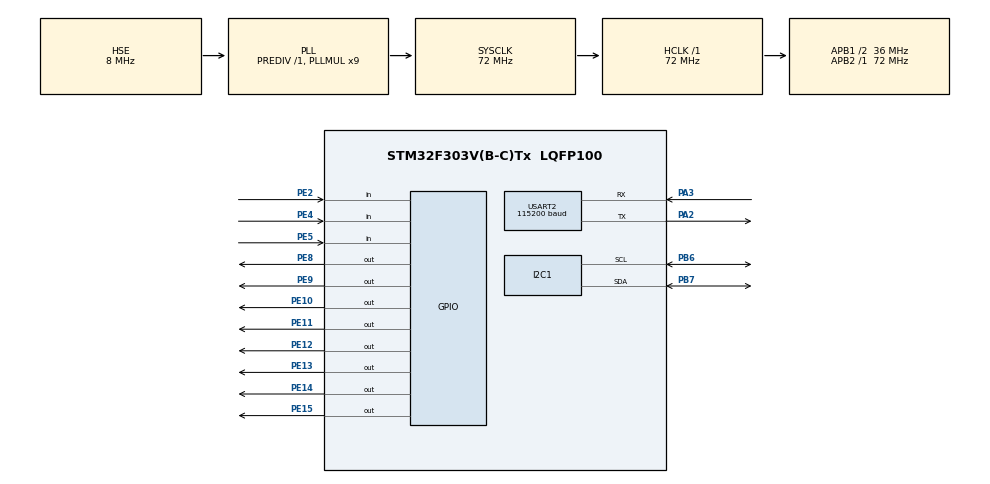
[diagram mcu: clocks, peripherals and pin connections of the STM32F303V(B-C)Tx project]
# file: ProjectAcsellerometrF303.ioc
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I2C1.Timing=0x2000090E
Mcu.Family=STM32F3
Mcu.Name=STM32F303V(B-C)Tx
Mcu.Package=LQFP100
NVIC.PriorityGroup=NVIC_PRIORITYGROUP_4
PA2.Mode=Asynchronous
PA2.Signal=USART2_TX
PA3.Mode=Asynchronous
PA3.Signal=USART2_RX
PB6.Mode=I2C
PB6.Signal=I2C1_SCL
PB7.Mode=I2C
PB7.Signal=I2C1_SDA
PE10.Signal=GPIO_Output
PE11.Signal=GPIO_Output
PE12.Signal=GPIO_Output
PE13.Signal=GPIO_Output
PE14.Signal=GPIO_Output
PE15.Signal=GPIO_Output
PE2.Signal=GPIO_Input
PE4.Signal=GPIO_Input
PE5.Signal=GPIO_Input
PE8.Signal=GPIO_Output
PE9.Signal=GPIO_Output
PF0-OSC_IN.Mode=HSE-External-Oscillator
PF0-OSC_IN.Signal=RCC_OSC_IN
PF1-OSC_OUT.Mode=HSE-External-Oscillator
PF1-OSC_OUT.Signal=RCC_OSC_OUT
ProjectManager.HeapSize=0x200
ProjectManager.StackSize=0x400
ProjectManager.TargetToolchain=MDK-ARM V5
RCC.AHBFreq_Value=72000000
RCC.APB1CLKDivider=RCC_HCLK_DIV2
RCC.APB1Freq_Value=36000000
RCC.APB1TimFreq_Value=72000000
RCC.APB2Freq_Value=72000000
RCC.APB2TimFreq_Value=72000000
RCC.CortexFreq_Value=72000000
RCC.HCLKFreq_Value=72000000
RCC.HSE_VALUE=8000000
RCC.HSI_VALUE=8000000
RCC.LSE_VALUE=32768
RCC.PLLMUL=RCC_PLL_MUL9
RCC.PLLSourceVirtual=RCC_PLLSOURCE_HSE
RCC.SYSCLKFreq_VALUE=72000000
RCC.SYSCLKSourceVirtual=RCC_SYSCLKSOURCE_PLLCLK
RCC.USBFreq_Value=72000000
USART2.BaudRate=115200
USART2.VirtualMode-Asynchronous=VM_ASYNC
board=ProjectAcsellerometrF303

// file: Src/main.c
/**
  ******************************************************************************
  * File Name          : main.c
  * Description        : Main program body
  ******************************************************************************
  ** This notice applies to any and all portions of this file
  * that are not between comment pairs USER CODE BEGIN and
  * USER CODE END. Other portions of this file, whether
  * inserted by the user or by software development tools
  * are owned by their respective copyright owners.
  *
  * COPYRIGHT(c) 2017 STMicroelectronics
  *
  * Redistribution and use in source and binary forms, with or without modification,
  * are permitted provided that the following conditions are met:
  *   1. Redistributions of source code must retain the above copyright notice,
  *      this list of conditions and the following disclaimer.
  *   2. Redistributions in binary form must reproduce the above copyright notice,
  *      this list of conditions and the following disclaimer in the documentation
  *      and/or other materials provided with the distribution.
  *   3. Neither the name of STMicroelectronics nor the names of its contributors
  *      may be used to endorse or promote products derived from this software
  *      without specific prior written permission.
  *
  * THIS SOFTWARE IS PROVIDED BY THE COPYRIGHT HOLDERS AND CONTRIBUTORS "AS IS"
  * AND ANY EXPRESS OR IMPLIED WARRANTIES, INCLUDING, BUT NOT LIMITED TO, THE
  * IMPLIED WARRANTIES OF MERCHANTABILITY AND FITNESS FOR A PARTICULAR PURPOSE ARE
  * DISCLAIMED. IN NO EVENT SHALL THE COPYRIGHT HOLDER OR CONTRIBUTORS BE LIABLE
  * FOR ANY DIRECT, INDIRECT, INCIDENTAL, SPECIAL, EXEMPLARY, OR CONSEQUENTIAL
  * DAMAGES (INCLUDING, BUT NOT LIMITED TO, PROCUREMENT OF SUBSTITUTE GOODS OR
  * SERVICES; LOSS OF USE, DATA, OR PROFITS; OR BUSINESS INTERRUPTION) HOWEVER
  * CAUSED AND ON ANY THEORY OF LIABILITY, WHETHER IN CONTRACT, STRICT LIABILITY,
  * OR TORT (INCLUDING NEGLIGENCE OR OTHERWISE) ARISING IN ANY WAY OUT OF THE USE
  * OF THIS SOFTWARE, EVEN IF ADVISED OF THE POSSIBILITY OF SUCH DAMAGE.
  *
  ******************************************************************************
  */

#include "stm32f3xx_hal.h"

/* USER CODE BEGIN Includes */
#include "main.h"
/* USER CODE END Includes */

I2C_HandleTypeDef hi2c1;

UART_HandleTypeDef huart2;

/* USER CODE BEGIN PV */
/* Private variables ---------------------------------------------------------*/

/* USER CODE END PV */

void SystemClock_Config(void);
static void MX_GPIO_Init(void);
static void MX_I2C1_Init(void);
static void MX_USART2_UART_Init(void);

/* USER CODE BEGIN PFP */
/* Private function prototypes -----------------------------------------------*/

/* USER CODE END PFP */

int main(void)
{

  /* MCU Configuration----------------------------------------------------------*/

  /* Reset of all peripherals, Initializes the Flash interface and the Systick. */
  HAL_Init();

  /* Configure the system clock */
  SystemClock_Config();

  /* Initialize all configured peripherals */
  MX_GPIO_Init();
  MX_I2C1_Init();
  MX_USART2_UART_Init();

  /* USER CODE BEGIN 2 */
		Accel_Ini();
  /* USER CODE END 2 */

  /* Infinite loop */
  while (1)
  {
		Accel_ReadAcc();
  }

}

/** System Clock Configuration
*/
void SystemClock_Config(void)
{

  RCC_OscInitTypeDef RCC_OscInitStruct;
  RCC_ClkInitTypeDef RCC_ClkInitStruct;
  RCC_PeriphCLKInitTypeDef PeriphClkInit;

    /**Initializes the CPU, AHB and APB busses clocks
    */
  RCC_OscInitStruct.OscillatorType = RCC_OSCILLATORTYPE_HSI|RCC_OSCILLATORTYPE_HSE;
  RCC_OscInitStruct.HSEState = RCC_HSE_ON;
  RCC_OscInitStruct.HSEPredivValue = RCC_HSE_PREDIV_DIV1;
  RCC_OscInitStruct.HSIState = RCC_HSI_ON;
  RCC_OscInitStruct.HSICalibrationValue = 16;
  RCC_OscInitStruct.PLL.PLLState = RCC_PLL_ON;
  RCC_OscInitStruct.PLL.PLLSource = RCC_PLLSOURCE_HSE;
  RCC_OscInitStruct.PLL.PLLMUL = RCC_PLL_MUL9;
  if (HAL_RCC_OscConfig(&RCC_OscInitStruct) != HAL_OK)
  {
    _Error_Handler(__FILE__, __LINE__);
  }

    /**Initializes the CPU, AHB and APB busses clocks
    */
  RCC_ClkInitStruct.ClockType = RCC_CLOCKTYPE_HCLK|RCC_CLOCKTYPE_SYSCLK
                              |RCC_CLOCKTYPE_PCLK1|RCC_CLOCKTYPE_PCLK2;
  RCC_ClkInitStruct.SYSCLKSource = RCC_SYSCLKSOURCE_PLLCLK;
  RCC_ClkInitStruct.AHBCLKDivider = RCC_SYSCLK_DIV1;
  RCC_ClkInitStruct.APB1CLKDivider = RCC_HCLK_DIV2;
  RCC_ClkInitStruct.APB2CLKDivider = RCC_HCLK_DIV1;

  if (HAL_RCC_ClockConfig(&RCC_ClkInitStruct, FLASH_LATENCY_2) != HAL_OK)
  {
    _Error_Handler(__FILE__, __LINE__);
  }

  PeriphClkInit.PeriphClockSelection = RCC_PERIPHCLK_USART2|RCC_PERIPHCLK_I2C1;
  PeriphClkInit.Usart2ClockSelection = RCC_USART2CLKSOURCE_PCLK1;
  PeriphClkInit.I2c1ClockSelection = RCC_I2C1CLKSOURCE_HSI;
  if (HAL_RCCEx_PeriphCLKConfig(&PeriphClkInit) != HAL_OK)
  {
    _Error_Handler(__FILE__, __LINE__);
  }

    /**Configure the Systick interrupt time
    */
  HAL_SYSTICK_Config(HAL_RCC_GetHCLKFreq()/1000);

    /**Configure the Systick
    */
  HAL_SYSTICK_CLKSourceConfig(SYSTICK_CLKSOURCE_HCLK);

  /* SysTick_IRQn interrupt configuration */
  HAL_NVIC_SetPriority(SysTick_IRQn, 0, 0);
}

/* I2C1 init function */
static void MX_I2C1_Init(void)
{

  hi2c1.Instance = I2C1;
  hi2c1.Init.Timing = 0x2000090E;
  hi2c1.Init.OwnAddress1 = 0;
  hi2c1.Init.AddressingMode = I2C_ADDRESSINGMODE_7BIT;
  hi2c1.Init.DualAddressMode = I2C_DUALADDRESS_DISABLE;
  hi2c1.Init.OwnAddress2 = 0;
  hi2c1.Init.OwnAddress2Masks = I2C_OA2_NOMASK;
  hi2c1.Init.GeneralCallMode = I2C_GENERALCALL_DISABLE;
  hi2c1.Init.NoStretchMode = I2C_NOSTRETCH_DISABLE;
  if (HAL_I2C_Init(&hi2c1) != HAL_OK)
  {
    _Error_Handler(__FILE__, __LINE__);
  }

    /**Configure Analogue filter
    */
  if (HAL_I2CEx_ConfigAnalogFilter(&hi2c1, I2C_ANALOGFILTER_ENABLE) != HAL_OK)
  {
    _Error_Handler(__FILE__, __LINE__);
  }

    /**Configure Digital filter
    */
  if (HAL_I2CEx_ConfigDigitalFilter(&hi2c1, 0) != HAL_OK)
  {
    _Error_Handler(__FILE__, __LINE__);
  }

}

/* USART2 init function */
static void MX_USART2_UART_Init(void)
{

  huart2.Instance = USART2;
  huart2.Init.BaudRate = 115200;
  huart2.Init.WordLength = UART_WORDLENGTH_8B;
  huart2.Init.StopBits = UART_STOPBITS_1;
  huart2.Init.Parity = UART_PARITY_NONE;
  huart2.Init.Mode = UART_MODE_TX_RX;
  huart2.Init.HwFlowCtl = UART_HWCONTROL_NONE;
  huart2.Init.OverSampling = UART_OVERSAMPLING_16;
  huart2.Init.OneBitSampling = UART_ONE_BIT_SAMPLE_DISABLE;
  huart2.AdvancedInit.AdvFeatureInit = UART_ADVFEATURE_NO_INIT;
  if (HAL_UART_Init(&huart2) != HAL_OK)
  {
    _Error_Handler(__FILE__, __LINE__);
  }

}

/** Configure pins as
        * Analog
        * Input
        * Output
        * EVENT_OUT
        * EXTI
*/
static void MX_GPIO_Init(void)
{

  GPIO_InitTypeDef GPIO_InitStruct;

  /* GPIO Ports Clock Enable */
  __HAL_RCC_GPIOE_CLK_ENABLE();
  __HAL_RCC_GPIOF_CLK_ENABLE();
  __HAL_RCC_GPIOA_CLK_ENABLE();
  __HAL_RCC_GPIOB_CLK_ENABLE();

  /*Configure GPIO pin Output Level */
  HAL_GPIO_WritePin(GPIOE, GPIO_PIN_8|GPIO_PIN_9|GPIO_PIN_10|GPIO_PIN_11
                          |GPIO_PIN_12|GPIO_PIN_13|GPIO_PIN_14|GPIO_PIN_15, GPIO_PIN_RESET);

  /*Configure GPIO pins : PE2 PE4 PE5 */
  GPIO_InitStruct.Pin = GPIO_PIN_2|GPIO_PIN_4|GPIO_PIN_5;
  GPIO_InitStruct.Mode = GPIO_MODE_INPUT;
  GPIO_InitStruct.Pull = GPIO_NOPULL;
  HAL_GPIO_Init(GPIOE, &GPIO_InitStruct);

  /*Configure GPIO pins : PE8 PE9 PE10 PE11
                           PE12 PE13 PE14 PE15 */
  GPIO_InitStruct.Pin = GPIO_PIN_8|GPIO_PIN_9|GPIO_PIN_10|GPIO_PIN_11
                          |GPIO_PIN_12|GPIO_PIN_13|GPIO_PIN_14|GPIO_PIN_15;
  GPIO_InitStruct.Mode = GPIO_MODE_OUTPUT_PP;
  GPIO_InitStruct.Pull = GPIO_NOPULL;
  GPIO_InitStruct.Speed = GPIO_SPEED_FREQ_LOW;
  HAL_GPIO_Init(GPIOE, &GPIO_InitStruct);

}

void _Error_Handler(char * file, int line)
{
  while(1)
  {
  }
}

/************************ (C) COPYRIGHT STMicroelectronics *****END OF FILE****/
